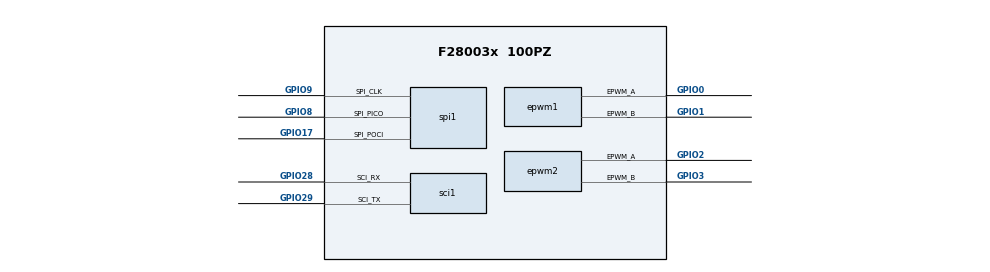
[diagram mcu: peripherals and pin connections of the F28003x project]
/**
 * @cliArgs --device "F28003x" --part "F28003x_100PZ" --package "100PZ" --context "system" --product "gmp_pro@1.00.00.05" --product "gmp_pro@1.00.00.05" --product "C2000WARE@5.03.00.00"
 * @versions {"tool":"1.21.0+3721"}
 */

/**
 * Import the modules used in this configuration.
 */
const adc            = scripting.addModule("/driverlib/adc.js", {}, false);
const adc1           = adc.addInstance();
const adc2           = adc.addInstance();
const adc3           = adc.addInstance();
const device_support = scripting.addModule("/driverlib/device_support.js");
const epwm           = scripting.addModule("/driverlib/epwm.js", {}, false);
const epwm1          = epwm.addInstance();
const epwm2          = epwm.addInstance();
const epwm3          = epwm.addInstance();
const sci            = scripting.addModule("/driverlib/sci.js", {}, false);
const sci1           = sci.addInstance();
const spi            = scripting.addModule("/driverlib/spi.js", {}, false);
const spi1           = spi.addInstance();

/**
 * Write custom configuration values to the imported modules.
 */
adc1.adcClockPrescaler              = "ADC_CLK_DIV_2_0";
adc1.enabledInts                    = ["ADC_INT_NUMBER1"];
adc1.enableInterrupt1ContinuousMode = true;
adc1.enableInterrupt1               = true;
adc1.$name                          = "ADCU";
adc1.enabledSOCs                    = ["ADC_SOC_NUMBER0","ADC_SOC_NUMBER1","ADC_SOC_NUMBER2"];
adc1.soc0Channel                    = "ADC_CH_ADCIN11";
adc1.soc1Channel                    = "ADC_CH_ADCIN2";
adc1.soc2Channel                    = "ADC_CH_ADCIN6";
adc1.soc0Trigger                    = "ADC_TRIGGER_EPWM1_SOCA";
adc1.soc0SampleWindow               = 9;
adc1.soc1SampleWindow               = 9;
adc1.soc1Trigger                    = "ADC_TRIGGER_EPWM1_SOCA";
adc1.soc2SampleWindow               = 9;
adc1.soc2Trigger                    = "ADC_TRIGGER_EPWM1_SOCA";
adc1.interruptPulseMode             = "ADC_PULSE_END_OF_CONV";
adc1.interrupt1SOCSource            = "ADC_SOC_NUMBER2";
adc1.socHighPriorityMode            = "ADC_PRI_THRU_SOC2_HIPRI";
adc1.registerInterrupts             = ["1"];
adc1.soc1IndependentNameMode        = true;
adc1.soc0IndependentNameMode        = true;
adc1.soc0Name                       = "MOTOR_IU";
adc1.soc1Name                       = "MOTOR_VU";
adc1.soc2IndependentNameMode        = true;
adc1.soc2Name                       = "MOTOR_VDC";
adc1.adcInt1.$name                  = "ADC1MainISR";
adc1.adcInt1.interruptHandler       = "MainISR";
adc1.adcInt1.enableInterrupt        = true;

adc2.$name                   = "ADCV";
adc2.adcBase                 = "ADCB_BASE";
adc2.adcClockPrescaler       = "ADC_CLK_DIV_2_0";
adc2.enabledSOCs             = ["ADC_SOC_NUMBER0","ADC_SOC_NUMBER1"];
adc2.soc0SampleWindow        = 9;
adc2.soc0Channel             = "ADC_CH_ADCIN12";
adc2.soc0Trigger             = "ADC_TRIGGER_EPWM1_SOCA";
adc2.soc1Channel             = "ADC_CH_ADCIN9";
adc2.soc1Trigger             = "ADC_TRIGGER_EPWM1_SOCA";
adc2.soc1SampleWindow        = 9;
adc2.socHighPriorityMode     = "ADC_PRI_THRU_SOC1_HIPRI";
adc2.soc0IndependentNameMode = true;
adc2.soc1IndependentNameMode = true;
adc2.soc0Name                = "MOTOR_IV";
adc2.soc1Name                = "MOTOR_VV";

adc3.$name                   = "ADCW";
adc3.adcBase                 = "ADCC_BASE";
adc3.adcClockPrescaler       = "ADC_CLK_DIV_2_0";
adc3.enabledSOCs             = ["ADC_SOC_NUMBER0","ADC_SOC_NUMBER1"];
adc3.soc0Channel             = "ADC_CH_ADCIN3";
adc3.soc1Channel             = "ADC_CH_ADCIN4";
adc3.soc0Trigger             = "ADC_TRIGGER_EPWM1_SOCA";
adc3.soc0SampleWindow        = 9;
adc3.soc1Trigger             = "ADC_TRIGGER_EPWM1_SOCA";
adc3.soc1SampleWindow        = 9;
adc3.socHighPriorityMode     = "ADC_PRI_THRU_SOC1_HIPRI";
adc3.soc0Name                = "MOTOR_IW";
adc3.soc0IndependentNameMode = true;
adc3.soc1IndependentNameMode = true;
adc3.soc1Name                = "MOTOR_VW";

const analog  = scripting.addModule("/driverlib/analog.js", {}, false);
const analog1 = analog.addInstance({}, false);
analog1.$name = "myANALOGPinMux0";
adc1.analog   = analog1;
adc2.analog   = analog1;
adc3.analog   = analog1;

const divider5       = system.clockTree["PLL_REFDIV"];
divider5.divideValue = 2;

const mux3       = system.clockTree["OSCCLKSRCSEL"];
mux3.inputSelect = "X1_XTAL";

epwm1.$name                                                      = "EPWMU";
epwm1.epwmTimebase_hsClockDiv                                    = "EPWM_HSCLOCK_DIVIDER_1";
epwm1.epwmTimebase_counterMode                                   = "EPWM_COUNTER_MODE_UP_DOWN";
epwm1.epwmTimebase_counterModeAfterSync                          = "EPWM_COUNT_MODE_UP_AFTER_SYNC";
epwm1.epwmTimebase_phaseEnable                                   = true;
epwm1.epwmTimebase_syncOutPulseMode                              = ["EPWM_SYNC_OUT_PULSE_ON_CNTR_ZERO"];
epwm1.epwmCounterCompare_cmpA                                    = 3000;
epwm1.epwmCounterCompare_shadowLoadModeCMPA                      = "EPWM_COMP_LOAD_ON_CNTR_ZERO_PERIOD";
epwm1.epwmActionQualifier_EPWM_AQ_OUTPUT_A_ON_TIMEBASE_UP_CMPA   = "EPWM_AQ_OUTPUT_LOW";
epwm1.epwmActionQualifier_EPWM_AQ_OUTPUT_A_ON_TIMEBASE_DOWN_CMPA = "EPWM_AQ_OUTPUT_HIGH";
epwm1.epwmDeadband_delayRED                                      = 75;
epwm1.epwmDeadband_delayFED                                      = 75;
epwm1.epwmEventTrigger_EPWM_SOC_A_triggerEnable                  = true;
epwm1.epwmEventTrigger_EPWM_SOC_A_triggerSource                  = "EPWM_SOC_TBCTR_PERIOD";
epwm1.epwmEventTrigger_EPWM_SOC_A_triggerEventPrescalar          = "1";
epwm1.epwmDeadband_polarityFED                                   = "EPWM_DB_POLARITY_ACTIVE_LOW";
epwm1.epwmDeadband_enableRED                                     = true;
epwm1.epwmDeadband_enableFED                                     = true;
epwm1.epwmEventTrigger_enableInterrupt                           = true;
epwm1.epwmEventTrigger_interruptSource                           = "EPWM_INT_TBCTR_PERIOD";
epwm1.epwmEventTrigger_interruptEventCount                       = "1";
epwm1.generateCodeTemplate                                       = true;
epwm1.epwmTimebase_syncInPulseSource                             = "EPWM_SYNC_IN_PULSE_SRC_DISABLE";
epwm1.epwmTimebase_period                                        = 6000;
epwm1.epwm.$assign                                               = "EPWM1";
epwm1.epwm.epwm_aPin.$assign                                     = "GPIO0";
epwm1.epwm.epwm_bPin.$assign                                     = "GPIO1";

epwm2.$name                                                      = "EPWMV";
epwm2.copyUse                                                    = true;
epwm2.copyFrom                                                   = "EPWMU";
epwm2.epwmTimebase_hsClockDiv                                    = "EPWM_HSCLOCK_DIVIDER_1";
epwm2.epwmTimebase_period                                        = 6000;
epwm2.epwmTimebase_counterMode                                   = "EPWM_COUNTER_MODE_UP_DOWN";
epwm2.epwmTimebase_counterModeAfterSync                          = "EPWM_COUNT_MODE_UP_AFTER_SYNC";
epwm2.epwmTimebase_phaseEnable                                   = true;
epwm2.epwmTimebase_syncOutPulseMode                              = ["EPWM_SYNC_OUT_PULSE_ON_CNTR_ZERO"];
epwm2.epwmCounterCompare_cmpA                                    = 3000;
epwm2.epwmCounterCompare_shadowLoadModeCMPA                      = "EPWM_COMP_LOAD_ON_CNTR_ZERO_PERIOD";
epwm2.epwmActionQualifier_EPWM_AQ_OUTPUT_A_ON_TIMEBASE_UP_CMPA   = "EPWM_AQ_OUTPUT_LOW";
epwm2.epwmActionQualifier_EPWM_AQ_OUTPUT_A_ON_TIMEBASE_DOWN_CMPA = "EPWM_AQ_OUTPUT_HIGH";
epwm2.epwmDeadband_delayRED                                      = 75;
epwm2.epwmDeadband_delayFED                                      = 75;
epwm2.epwmDeadband_polarityFED                                   = "EPWM_DB_POLARITY_ACTIVE_LOW";
epwm2.epwmDeadband_enableRED                                     = true;
epwm2.epwmDeadband_enableFED                                     = true;
epwm2.epwm.$assign                                               = "EPWM2";
epwm2.epwm.epwm_aPin.$assign                                     = "GPIO2";
epwm2.epwm.epwm_bPin.$assign                                     = "GPIO3";

epwm3.$name                                                      = "EPWMW";
epwm3.copyUse                                                    = true;
epwm3.copyFrom                                                   = "EPWMV";
epwm3.epwmTimebase_hsClockDiv                                    = "EPWM_HSCLOCK_DIVIDER_1";
epwm3.epwmTimebase_period                                        = 6000;
epwm3.epwmTimebase_counterMode                                   = "EPWM_COUNTER_MODE_UP_DOWN";
epwm3.epwmTimebase_counterModeAfterSync                          = "EPWM_COUNT_MODE_UP_AFTER_SYNC";
epwm3.epwmTimebase_phaseEnable                                   = true;
epwm3.epwmCounterCompare_cmpA                                    = 3000;
epwm3.epwmCounterCompare_shadowLoadModeCMPA                      = "EPWM_COMP_LOAD_ON_CNTR_ZERO_PERIOD";
epwm3.epwmActionQualifier_EPWM_AQ_OUTPUT_A_ON_TIMEBASE_UP_CMPA   = "EPWM_AQ_OUTPUT_LOW";
epwm3.epwmActionQualifier_EPWM_AQ_OUTPUT_A_ON_TIMEBASE_DOWN_CMPA = "EPWM_AQ_OUTPUT_HIGH";
epwm3.epwmDeadband_delayRED                                      = 75;
epwm3.epwmDeadband_delayFED                                      = 75;
epwm3.epwmDeadband_polarityFED                                   = "EPWM_DB_POLARITY_ACTIVE_LOW";
epwm3.epwmDeadband_enableRED                                     = true;
epwm3.epwmDeadband_enableFED                                     = true;
epwm3.epwmActionQualifier_EPWM_AQ_OUTPUT_A_shadowMode            = true;
epwm3.epwmActionQualifier_EPWM_AQ_OUTPUT_A_gld                   = true;
epwm3.epwmCounterCompare_cmpAGld                                 = true;
epwm3.epwmCounterCompare_cmpB                                    = 2;
epwm3.epwmTimebase_syncOutPulseMode                              = ["EPWM_SYNC_OUT_PULSE_ON_CNTR_ZERO"];
epwm3.epwm.$assign                                               = "EPWM6";

sci1.$name                 = "debug_uart";
sci1.useInterrupts         = false;
sci1.sci.sci_rxPin.$assign = "GPIO28";
sci1.sci.sci_txPin.$assign = "GPIO29";
sci1.rxQual.$name          = "myGPIOQUAL0";
sci1.txQual.$name          = "myGPIOQUAL1";

spi1.$name                   = "Encoder_SPI";
spi1.useCase                 = "CUSTOM";
spi1.useInterfacePins        = ["SPI@_CLK","SPI@_SIMO","SPI@_SOMI"];
spi1.useInterrupts           = false;
spi1.spi.spi_picoPin.$assign = "GPIO8";
spi1.spi.spi_pociPin.$assign = "GPIO17";
spi1.spi.spi_clkPin.$assign  = "GPIO9";
spi1.clkQual.$name           = "myGPIOQUAL4";
spi1.picoQual.$name          = "myGPIOQUAL2";
spi1.pociQual.$name          = "myGPIOQUAL3";

/**
 * Pinmux solution for unlocked pins/peripherals. This ensures that minor changes to the automatic solver in a future
 * version of the tool will not impact the pinmux you originally saw.  These lines can be completely deleted in order to
 * re-solve from scratch.
 */
analog1.analog.$suggestSolution                           = "ANALOG";
analog1.analog["a0/b15/c15/daca_outPin"].$suggestSolution = "A0/B15/C15/DACA_OUT";
analog1.analog["a1/b7/dacb_outPin"].$suggestSolution      = "A1/B7/DACB_OUT";
analog1.analog["a10/b1/c10Pin"].$suggestSolution          = "A10/B1/C10";
analog1.analog["a11/b10/c0Pin"].$suggestSolution          = "A11/B10/C0";
analog1.analog["a12, c5Pin"].$suggestSolution             = "A12, C5";
analog1.analog["a14/b14/c4Pin"].$suggestSolution          = "A14/B14/C4";
analog1.analog["a2/b6/c9Pin"].$suggestSolution            = "A2/B6/C9";
analog1.analog["a3, c7/b9Pin"].$suggestSolution           = "A3, C7/B9";
analog1.analog["a4/b8Pin"].$suggestSolution               = "A4/B8";
analog1.analog.a5Pin.$suggestSolution                     = "A5";
analog1.analog.a6Pin.$suggestSolution                     = "A6";
analog1.analog.a8Pin.$suggestSolution                     = "A8";
analog1.analog.a9Pin.$suggestSolution                     = "A9";
analog1.analog["b0/c11Pin"].$suggestSolution              = "B0/C11";
analog1.analog.b11Pin.$suggestSolution                    = "B11";
analog1.analog["b11, gpio21Pin"].$suggestSolution         = "B11, GPIO21";
analog1.analog["b2/c6Pin"].$suggestSolution               = "B2/C6";
analog1.analog["b3/vdacPin"].$suggestSolution             = "B3/VDAC";
analog1.analog["b4/c8Pin"].$suggestSolution               = "B4/C8";
analog1.analog.b5Pin.$suggestSolution                     = "B5";
analog1.analog["b5, gpio20Pin"].$suggestSolution          = "B5, GPIO20";
analog1.analog.c1Pin.$suggestSolution                     = "C1";
analog1.analog.c14Pin.$suggestSolution                    = "C14";
analog1.analog["c2/b12Pin"].$suggestSolution              = "C2/B12";
analog1.analog["c3/a7Pin"].$suggestSolution               = "C3/A7";
epwm3.epwm.epwm_aPin.$suggestSolution                     = "GPIO10";
epwm3.epwm.epwm_bPin.$suggestSolution                     = "GPIO11";
sci1.sci.$suggestSolution                                 = "SCIA";
spi1.spi.$suggestSolution                                 = "SPIA";
